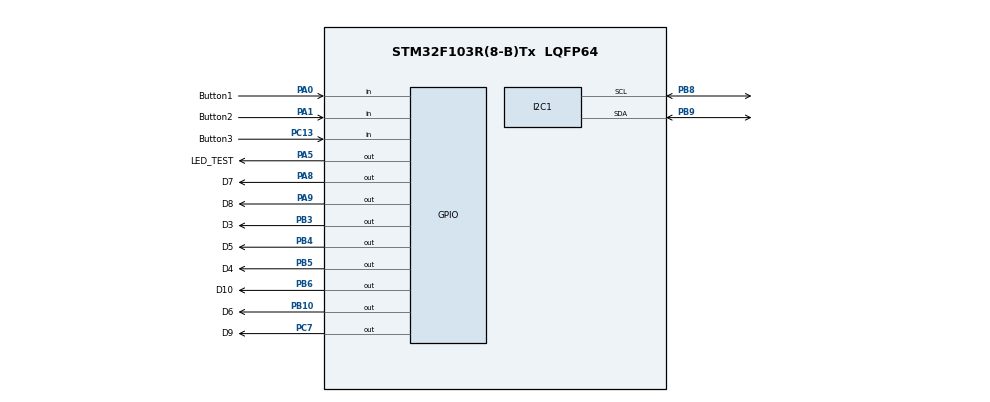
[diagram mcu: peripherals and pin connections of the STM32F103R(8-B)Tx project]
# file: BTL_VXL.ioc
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Mcu.Family=STM32F1
Mcu.Name=STM32F103R(8-B)Tx
Mcu.Package=LQFP64
NVIC.I2C1_ER_IRQn=true\:0\:0\:false\:false\:true\:true\:true
NVIC.I2C1_EV_IRQn=true\:0\:0\:false\:false\:true\:true\:true
NVIC.PriorityGroup=NVIC_PRIORITYGROUP_4
NVIC.TIM2_IRQn=true\:0\:0\:false\:false\:true\:true\:true
PA0-WKUP.GPIO_Label=Button1
PA0-WKUP.GPIO_PuPd=GPIO_PULLUP
PA0-WKUP.Signal=GPIO_Input
PA1.GPIO_Label=Button2
PA1.GPIO_PuPd=GPIO_PULLUP
PA1.Signal=GPIO_Input
PA13.Mode=Serial_Wire
PA13.Signal=SYS_JTMS-SWDIO
PA14.Mode=Serial_Wire
PA14.Signal=SYS_JTCK-SWCLK
PA5.GPIO_Label=LED_TEST
PA5.Signal=GPIO_Output
PA8.GPIO_Label=D7
PA8.Signal=GPIO_Output
PA9.GPIO_Label=D8
PA9.Signal=GPIO_Output
PB10.GPIO_Label=D6
PB10.Signal=GPIO_Output
PB3.GPIO_Label=D3
PB3.Signal=GPIO_Output
PB4.GPIO_Label=D5
PB4.Signal=GPIO_Output
PB5.GPIO_Label=D4
PB5.Signal=GPIO_Output
PB6.GPIO_Label=D10
PB6.Signal=GPIO_Output
PB8.Mode=I2C
PB8.Signal=I2C1_SCL
PB9.Mode=I2C
PB9.Signal=I2C1_SDA
PC13-TAMPER-RTC.GPIO_Label=Button3
PC13-TAMPER-RTC.GPIO_PuPd=GPIO_PULLUP
PC13-TAMPER-RTC.Signal=GPIO_Input
PC7.GPIO_Label=D9
PC7.Signal=GPIO_Output
ProjectManager.HeapSize=0x200
ProjectManager.StackSize=0x400
ProjectManager.TargetToolchain=STM32CubeIDE
RCC.APB1Freq_Value=8000000
RCC.APB2Freq_Value=8000000
TIM2.Period=9
TIM2.Prescaler=7999
VP_TIM2_VS_ClockSourceINT.Mode=Internal
board=custom

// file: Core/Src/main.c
/* USER CODE BEGIN Header */
/**
  ******************************************************************************
  * @file           : main.c
  * @brief          : Main program body
  ******************************************************************************
  * @attention
  *
  * <h2><center>&copy; Copyright (c) 2024 STMicroelectronics.
  * All rights reserved.</center></h2>
  *
  * This software component is licensed by ST under BSD 3-Clause license,
  * the "License"; You may not use this file except in compliance with the
  * License. You may obtain a copy of the License at:
  *                        opensource.org/licenses/BSD-3-Clause
  *
  ******************************************************************************
  */
/* USER CODE END Header */
#include "main.h"

I2C_HandleTypeDef hi2c1;

TIM_HandleTypeDef htim2;

void SystemClock_Config(void);
static void MX_TIM2_Init(void);
static void MX_GPIO_Init(void);
static void MX_I2C1_Init(void);

int main(void)
{

  /* MCU Configuration--------------------------------------------------------*/

  /* Reset of all peripherals, Initializes the Flash interface and the Systick. */
  HAL_Init();

  /* Configure the system clock */
  SystemClock_Config();

  /* Initialize all configured peripherals */
  MX_TIM2_Init();
  MX_GPIO_Init();
  MX_I2C1_Init();
  /* USER CODE BEGIN 2 */
  HAL_TIM_Base_Start_IT(&htim2);
  lcd_init();
  /* USER CODE END 2 */

  /* Infinite loop */
  /* USER CODE BEGIN WHILE */
  lcd_update_buffer();
  lcd_clear_display();
  //  setTimer0(3000);

//  lcd_goto_XY(1, 1);
//  //char c[] = "123";
//  lcd_send_string("456");
  while(1)
  {
//	  HAL_GPIO_TogglePin(LED_TEST_GPIO_Port, LED_TEST_Pin);
//	  HAL_Delay(1000);

//	  HAL_Delay(1000);
	  fsm_normal_run();
	  fsm_manual_run();
//	  fsm_setting_run();
    /* USER CODE END WHILE */

  }
}

void SystemClock_Config(void)
{
  RCC_OscInitTypeDef RCC_OscInitStruct = {0};
  RCC_ClkInitTypeDef RCC_ClkInitStruct = {0};

  /** Initializes the RCC Oscillators according to the specified parameters
  * in the RCC_OscInitTypeDef structure.
  */
  RCC_OscInitStruct.OscillatorType = RCC_OSCILLATORTYPE_HSI;
  RCC_OscInitStruct.HSIState = RCC_HSI_ON;
  RCC_OscInitStruct.HSICalibrationValue = RCC_HSICALIBRATION_DEFAULT;
  RCC_OscInitStruct.PLL.PLLState = RCC_PLL_NONE;
  if (HAL_RCC_OscConfig(&RCC_OscInitStruct) != HAL_OK)
  {
    Error_Handler();
  }
  /** Initializes the CPU, AHB and APB buses clocks
  */
  RCC_ClkInitStruct.ClockType = RCC_CLOCKTYPE_HCLK|RCC_CLOCKTYPE_SYSCLK
                              |RCC_CLOCKTYPE_PCLK1|RCC_CLOCKTYPE_PCLK2;
  RCC_ClkInitStruct.SYSCLKSource = RCC_SYSCLKSOURCE_HSI;
  RCC_ClkInitStruct.AHBCLKDivider = RCC_SYSCLK_DIV1;
  RCC_ClkInitStruct.APB1CLKDivider = RCC_HCLK_DIV1;
  RCC_ClkInitStruct.APB2CLKDivider = RCC_HCLK_DIV1;

  if (HAL_RCC_ClockConfig(&RCC_ClkInitStruct, FLASH_LATENCY_0) != HAL_OK)
  {
    Error_Handler();
  }
}

static void MX_I2C1_Init(void)
{

  hi2c1.Instance = I2C1;
  hi2c1.Init.ClockSpeed = 100000;
  hi2c1.Init.DutyCycle = I2C_DUTYCYCLE_2;
  hi2c1.Init.OwnAddress1 = 0;
  hi2c1.Init.AddressingMode = I2C_ADDRESSINGMODE_7BIT;
  hi2c1.Init.DualAddressMode = I2C_DUALADDRESS_DISABLE;
  hi2c1.Init.OwnAddress2 = 0;
  hi2c1.Init.GeneralCallMode = I2C_GENERALCALL_DISABLE;
  hi2c1.Init.NoStretchMode = I2C_NOSTRETCH_DISABLE;
  if (HAL_I2C_Init(&hi2c1) != HAL_OK)
  {
    Error_Handler();
  }

}

static void MX_TIM2_Init(void)
{

  TIM_ClockConfigTypeDef sClockSourceConfig = {0};
  TIM_MasterConfigTypeDef sMasterConfig = {0};

  htim2.Instance = TIM2;
  htim2.Init.Prescaler = 7999;
  htim2.Init.CounterMode = TIM_COUNTERMODE_UP;
  htim2.Init.Period = 9;
  htim2.Init.ClockDivision = TIM_CLOCKDIVISION_DIV1;
  htim2.Init.AutoReloadPreload = TIM_AUTORELOAD_PRELOAD_DISABLE;
  if (HAL_TIM_Base_Init(&htim2) != HAL_OK)
  {
    Error_Handler();
  }
  sClockSourceConfig.ClockSource = TIM_CLOCKSOURCE_INTERNAL;
  if (HAL_TIM_ConfigClockSource(&htim2, &sClockSourceConfig) != HAL_OK)
  {
    Error_Handler();
  }
  sMasterConfig.MasterOutputTrigger = TIM_TRGO_RESET;
  sMasterConfig.MasterSlaveMode = TIM_MASTERSLAVEMODE_DISABLE;
  if (HAL_TIMEx_MasterConfigSynchronization(&htim2, &sMasterConfig) != HAL_OK)
  {
    Error_Handler();
  }

}

static void MX_GPIO_Init(void)
{
  GPIO_InitTypeDef GPIO_InitStruct = {0};

  /* GPIO Ports Clock Enable */
  __HAL_RCC_GPIOC_CLK_ENABLE();
  __HAL_RCC_GPIOA_CLK_ENABLE();
  __HAL_RCC_GPIOB_CLK_ENABLE();

  /*Configure GPIO pin Output Level */
  HAL_GPIO_WritePin(GPIOA, LED_TEST_Pin|D7_Pin|D8_Pin, GPIO_PIN_RESET);

  /*Configure GPIO pin Output Level */
  HAL_GPIO_WritePin(GPIOB, D6_Pin|D3_Pin|D5_Pin|D4_Pin
                          |D10_Pin, GPIO_PIN_RESET);

  /*Configure GPIO pin Output Level */
  HAL_GPIO_WritePin(D9_GPIO_Port, D9_Pin, GPIO_PIN_RESET);

  /*Configure GPIO pin : Button3_Pin */
  GPIO_InitStruct.Pin = Button3_Pin;
  GPIO_InitStruct.Mode = GPIO_MODE_INPUT;
  GPIO_InitStruct.Pull = GPIO_PULLUP;
  HAL_GPIO_Init(Button3_GPIO_Port, &GPIO_InitStruct);

  /*Configure GPIO pins : Button1_Pin Button2_Pin */
  GPIO_InitStruct.Pin = Button1_Pin|Button2_Pin;
  GPIO_InitStruct.Mode = GPIO_MODE_INPUT;
  GPIO_InitStruct.Pull = GPIO_PULLUP;
  HAL_GPIO_Init(GPIOA, &GPIO_InitStruct);

  /*Configure GPIO pins : LED_TEST_Pin D7_Pin D8_Pin */
  GPIO_InitStruct.Pin = LED_TEST_Pin|D7_Pin|D8_Pin;
  GPIO_InitStruct.Mode = GPIO_MODE_OUTPUT_PP;
  GPIO_InitStruct.Pull = GPIO_NOPULL;
  GPIO_InitStruct.Speed = GPIO_SPEED_FREQ_LOW;
  HAL_GPIO_Init(GPIOA, &GPIO_InitStruct);

  /*Configure GPIO pins : D6_Pin D3_Pin D5_Pin D4_Pin
                           D10_Pin */
  GPIO_InitStruct.Pin = D6_Pin|D3_Pin|D5_Pin|D4_Pin
                          |D10_Pin;
  GPIO_InitStruct.Mode = GPIO_MODE_OUTPUT_PP;
  GPIO_InitStruct.Pull = GPIO_NOPULL;
  GPIO_InitStruct.Speed = GPIO_SPEED_FREQ_LOW;
  HAL_GPIO_Init(GPIOB, &GPIO_InitStruct);

  /*Configure GPIO pin : D9_Pin */
  GPIO_InitStruct.Pin = D9_Pin;
  GPIO_InitStruct.Mode = GPIO_MODE_OUTPUT_PP;
  GPIO_InitStruct.Pull = GPIO_NOPULL;
  GPIO_InitStruct.Speed = GPIO_SPEED_FREQ_LOW;
  HAL_GPIO_Init(D9_GPIO_Port, &GPIO_InitStruct);

}

/* USER CODE BEGIN 4 */
void HAL_TIM_PeriodElapsedCallback(TIM_HandleTypeDef *htim)
{
	if(htim->Instance == TIM2)
	{
		timerRun();
		button_reading();
	}
}
/* USER CODE END 4 */

void Error_Handler(void)
{
  __disable_irq();
  while (1)
  {
  }
}

/************************ (C) COPYRIGHT STMicroelectronics *****END OF FILE****/
